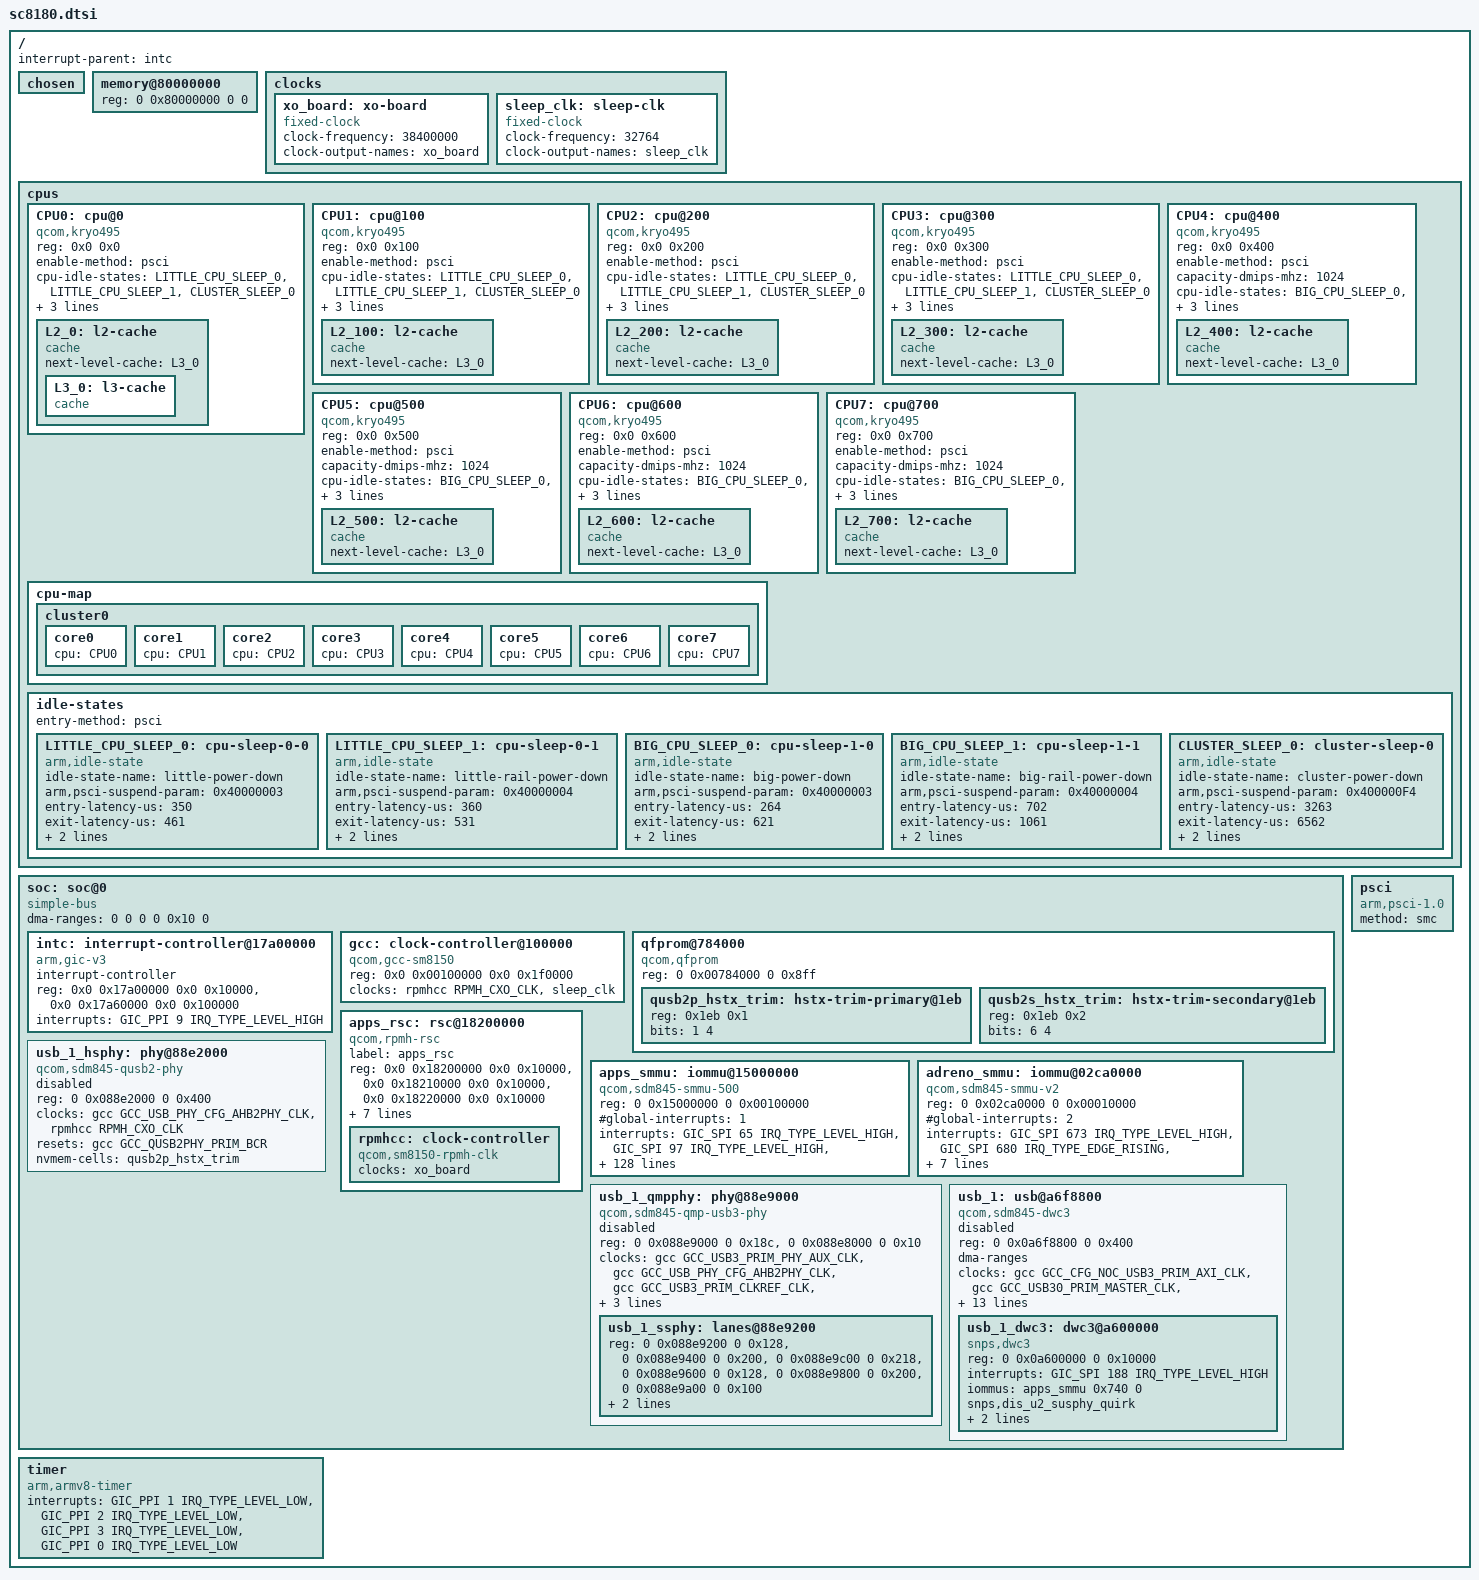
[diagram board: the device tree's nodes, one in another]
// SPDX-License-Identifier: BSD-3-Clause
#include <dt-bindings/clock/qcom,gcc-sdm845.h>
#include <dt-bindings/interrupt-controller/arm-gic.h>
#include <dt-bindings/phy/phy-qcom-qusb2.h>
#include <dt-bindings/soc/qcom,rpmh-rsc.h>
#include <dt-bindings/clock/qcom,rpmh.h>

/ {
	interrupt-parent = <&intc>;

	#address-cells = <2>;
	#size-cells = <2>;

	chosen { };

	memory@80000000 {
		device_type = "memory";
		/* We expect the bootloader to fill in the size */
		reg = <0 0x80000000 0 0>;
	};

	clocks {
		xo_board: xo-board {
			compatible = "fixed-clock";
			#clock-cells = <0>;
			clock-frequency = <38400000>;
			clock-output-names = "xo_board";
		};

		sleep_clk: sleep-clk {
			compatible = "fixed-clock";
			#clock-cells = <0>;
			clock-frequency = <32764>;
			clock-output-names = "sleep_clk";
		};
	};

	cpus {
		#address-cells = <2>;
		#size-cells = <0>;

		CPU0: cpu@0 {
			device_type = "cpu";
			compatible = "qcom,kryo495";
			reg = <0x0 0x0>;
			enable-method = "psci";
			cpu-idle-states = <&LITTLE_CPU_SLEEP_0
					   &LITTLE_CPU_SLEEP_1
					   &CLUSTER_SLEEP_0>;
			capacity-dmips-mhz = <607>;
			dynamic-power-coefficient = <100>;
			#cooling-cells = <2>;
			next-level-cache = <&L2_0>;
			L2_0: l2-cache {
				compatible = "cache";
				next-level-cache = <&L3_0>;
				L3_0: l3-cache {
				      compatible = "cache";
				};
			};
		};

		CPU1: cpu@100 {
			device_type = "cpu";
			compatible = "qcom,kryo495";
			reg = <0x0 0x100>;
			enable-method = "psci";
			cpu-idle-states = <&LITTLE_CPU_SLEEP_0
					   &LITTLE_CPU_SLEEP_1
					   &CLUSTER_SLEEP_0>;
			capacity-dmips-mhz = <607>;
			dynamic-power-coefficient = <100>;
			#cooling-cells = <2>;
			next-level-cache = <&L2_100>;
			L2_100: l2-cache {
				compatible = "cache";
				next-level-cache = <&L3_0>;
			};
		};

		CPU2: cpu@200 {
			device_type = "cpu";
			compatible = "qcom,kryo495";
			reg = <0x0 0x200>;
			enable-method = "psci";
			cpu-idle-states = <&LITTLE_CPU_SLEEP_0
					   &LITTLE_CPU_SLEEP_1
					   &CLUSTER_SLEEP_0>;
			capacity-dmips-mhz = <607>;
			dynamic-power-coefficient = <100>;
			#cooling-cells = <2>;
			next-level-cache = <&L2_200>;
			L2_200: l2-cache {
				compatible = "cache";
				next-level-cache = <&L3_0>;
			};
		};

		CPU3: cpu@300 {
			device_type = "cpu";
			compatible = "qcom,kryo495";
			reg = <0x0 0x300>;
			enable-method = "psci";
			cpu-idle-states = <&LITTLE_CPU_SLEEP_0
					   &LITTLE_CPU_SLEEP_1
					   &CLUSTER_SLEEP_0>;
			capacity-dmips-mhz = <607>;
			dynamic-power-coefficient = <100>;
			#cooling-cells = <2>;
			next-level-cache = <&L2_300>;
			L2_300: l2-cache {
				compatible = "cache";
				next-level-cache = <&L3_0>;
			};
		};

		CPU4: cpu@400 {
			device_type = "cpu";
			compatible = "qcom,kryo495";
			reg = <0x0 0x400>;
			enable-method = "psci";
			capacity-dmips-mhz = <1024>;
			cpu-idle-states = <&BIG_CPU_SLEEP_0
					   &BIG_CPU_SLEEP_1
					   &CLUSTER_SLEEP_0>;
			dynamic-power-coefficient = <396>;
			#cooling-cells = <2>;
			next-level-cache = <&L2_400>;
			L2_400: l2-cache {
				compatible = "cache";
				next-level-cache = <&L3_0>;
			};
		};

		CPU5: cpu@500 {
			device_type = "cpu";
			compatible = "qcom,kryo495";
			reg = <0x0 0x500>;
			enable-method = "psci";
			capacity-dmips-mhz = <1024>;
			cpu-idle-states = <&BIG_CPU_SLEEP_0
					   &BIG_CPU_SLEEP_1
					   &CLUSTER_SLEEP_0>;
			dynamic-power-coefficient = <396>;
			#cooling-cells = <2>;
			next-level-cache = <&L2_500>;
			L2_500: l2-cache {
				compatible = "cache";
				next-level-cache = <&L3_0>;
			};
		};

		CPU6: cpu@600 {
			device_type = "cpu";
			compatible = "qcom,kryo495";
			reg = <0x0 0x600>;
			enable-method = "psci";
			capacity-dmips-mhz = <1024>;
			cpu-idle-states = <&BIG_CPU_SLEEP_0
					   &BIG_CPU_SLEEP_1
					   &CLUSTER_SLEEP_0>;
			dynamic-power-coefficient = <396>;
			#cooling-cells = <2>;
			next-level-cache = <&L2_600>;
			L2_600: l2-cache {
				compatible = "cache";
				next-level-cache = <&L3_0>;
			};
		};

		CPU7: cpu@700 {
			device_type = "cpu";
			compatible = "qcom,kryo495";
			reg = <0x0 0x700>;
			enable-method = "psci";
			capacity-dmips-mhz = <1024>;
			cpu-idle-states = <&BIG_CPU_SLEEP_0
					   &BIG_CPU_SLEEP_1
					   &CLUSTER_SLEEP_0>;
			dynamic-power-coefficient = <396>;
			#cooling-cells = <2>;
			next-level-cache = <&L2_700>;
			L2_700: l2-cache {
				compatible = "cache";
				next-level-cache = <&L3_0>;
			};
		};

		cpu-map {
			cluster0 {
				core0 {
					cpu = <&CPU0>;
				};

				core1 {
					cpu = <&CPU1>;
				};

				core2 {
					cpu = <&CPU2>;
				};

				core3 {
					cpu = <&CPU3>;
				};

				core4 {
					cpu = <&CPU4>;
				};

				core5 {
					cpu = <&CPU5>;
				};

				core6 {
					cpu = <&CPU6>;
				};

				core7 {
					cpu = <&CPU7>;
				};
			};
		};

		idle-states {
			entry-method = "psci";

			LITTLE_CPU_SLEEP_0: cpu-sleep-0-0 {
				compatible = "arm,idle-state";
				idle-state-name = "little-power-down";
				arm,psci-suspend-param = <0x40000003>;
				entry-latency-us = <350>;
				exit-latency-us = <461>;
				min-residency-us = <1890>;
				local-timer-stop;
			};

			LITTLE_CPU_SLEEP_1: cpu-sleep-0-1 {
				compatible = "arm,idle-state";
				idle-state-name = "little-rail-power-down";
				arm,psci-suspend-param = <0x40000004>;
				entry-latency-us = <360>;
				exit-latency-us = <531>;
				min-residency-us = <3934>;
				local-timer-stop;
			};

			BIG_CPU_SLEEP_0: cpu-sleep-1-0 {
				compatible = "arm,idle-state";
				idle-state-name = "big-power-down";
				arm,psci-suspend-param = <0x40000003>;
				entry-latency-us = <264>;
				exit-latency-us = <621>;
				min-residency-us = <952>;
				local-timer-stop;
			};

			BIG_CPU_SLEEP_1: cpu-sleep-1-1 {
				compatible = "arm,idle-state";
				idle-state-name = "big-rail-power-down";
				arm,psci-suspend-param = <0x40000004>;
				entry-latency-us = <702>;
				exit-latency-us = <1061>;
				min-residency-us = <4488>;
				local-timer-stop;
			};

			CLUSTER_SLEEP_0: cluster-sleep-0 {
				compatible = "arm,idle-state";
				idle-state-name = "cluster-power-down";
				arm,psci-suspend-param = <0x400000F4>;
				entry-latency-us = <3263>;
				exit-latency-us = <6562>;
				min-residency-us = <9987>;
				local-timer-stop;
			};
		};
	};

	soc: soc@0 {
		#address-cells = <2>;
		#size-cells = <2>;
		ranges = <0 0 0 0 0x10 0>;
		dma-ranges = <0 0 0 0 0x10 0>;
		compatible = "simple-bus";

		intc: interrupt-controller@17a00000 {
			compatible = "arm,gic-v3";
			interrupt-controller;
			#interrupt-cells = <3>;
			reg = <0x0 0x17a00000 0x0 0x10000>,	/* GICD */
			      <0x0 0x17a60000 0x0 0x100000>;	/* GICR * 8 */
			interrupts = <GIC_PPI 9 IRQ_TYPE_LEVEL_HIGH>;
		};

		gcc: clock-controller@100000 {
			compatible = "qcom,gcc-sm8150";
			reg = <0x0 0x00100000 0x0 0x1f0000>;
			#clock-cells = <1>;
			#reset-cells = <1>;
			#power-domain-cells = <1>;
			clock-names = "bi_tcxo",
				      "sleep_clk";
			clocks = <&rpmhcc RPMH_CXO_CLK>,
				 <&sleep_clk>;
		};

		qfprom@784000 {
			compatible = "qcom,qfprom";
			reg = <0 0x00784000 0 0x8ff>;
			#address-cells = <1>;
			#size-cells = <1>;

			qusb2p_hstx_trim: hstx-trim-primary@1eb {
				reg = <0x1eb 0x1>;
				bits = <1 4>;
			};

			qusb2s_hstx_trim: hstx-trim-secondary@1eb {
				reg = <0x1eb 0x2>;
				bits = <6 4>;
			};
		};


		apps_rsc: rsc@18200000 {
			label = "apps_rsc";
			compatible = "qcom,rpmh-rsc";
			reg = <0x0 0x18200000 0x0 0x10000>,
			      <0x0 0x18210000 0x0 0x10000>,
			      <0x0 0x18220000 0x0 0x10000>;
			reg-names = "drv-0", "drv-1", "drv-2";
			interrupts = <GIC_SPI 3 IRQ_TYPE_LEVEL_HIGH>,
				     <GIC_SPI 4 IRQ_TYPE_LEVEL_HIGH>,
				     <GIC_SPI 5 IRQ_TYPE_LEVEL_HIGH>;
			qcom,tcs-offset = <0xd00>;
			qcom,drv-id = <2>;
			qcom,tcs-config = <ACTIVE_TCS  2>,
					  <SLEEP_TCS   1>,
					  <WAKE_TCS    1>,
					  <CONTROL_TCS 0>;

			rpmhcc: clock-controller {
				compatible = "qcom,sm8150-rpmh-clk";
				#clock-cells = <1>;
				clock-names = "xo";
				clocks = <&xo_board>;
			};
		};

		apps_smmu: iommu@15000000 {
			compatible = "qcom,sdm845-smmu-500", "arm,mmu-500";
			reg = <0 0x15000000 0 0x00100000>;
			#iommu-cells = <2>;
			#global-interrupts = <1>;
			interrupts = <GIC_SPI 65 IRQ_TYPE_LEVEL_HIGH>,
				     <GIC_SPI 97 IRQ_TYPE_LEVEL_HIGH>,
				     <GIC_SPI 98 IRQ_TYPE_LEVEL_HIGH>,
				     <GIC_SPI 99 IRQ_TYPE_LEVEL_HIGH>,
				     <GIC_SPI 100 IRQ_TYPE_LEVEL_HIGH>,
				     <GIC_SPI 101 IRQ_TYPE_LEVEL_HIGH>,
				     <GIC_SPI 102 IRQ_TYPE_LEVEL_HIGH>,
				     <GIC_SPI 103 IRQ_TYPE_LEVEL_HIGH>,
				     <GIC_SPI 104 IRQ_TYPE_LEVEL_HIGH>,
				     <GIC_SPI 105 IRQ_TYPE_LEVEL_HIGH>,
				     <GIC_SPI 106 IRQ_TYPE_LEVEL_HIGH>,
				     <GIC_SPI 107 IRQ_TYPE_LEVEL_HIGH>,
				     <GIC_SPI 108 IRQ_TYPE_LEVEL_HIGH>,
				     <GIC_SPI 109 IRQ_TYPE_LEVEL_HIGH>,
				     <GIC_SPI 110 IRQ_TYPE_LEVEL_HIGH>,
				     <GIC_SPI 111 IRQ_TYPE_LEVEL_HIGH>,
				     <GIC_SPI 112 IRQ_TYPE_LEVEL_HIGH>,
				     <GIC_SPI 113 IRQ_TYPE_LEVEL_HIGH>,
				     <GIC_SPI 114 IRQ_TYPE_LEVEL_HIGH>,
				     <GIC_SPI 115 IRQ_TYPE_LEVEL_HIGH>,
				     <GIC_SPI 116 IRQ_TYPE_LEVEL_HIGH>,
				     <GIC_SPI 117 IRQ_TYPE_LEVEL_HIGH>,
				     <GIC_SPI 118 IRQ_TYPE_LEVEL_HIGH>,
				     <GIC_SPI 181 IRQ_TYPE_LEVEL_HIGH>,
				     <GIC_SPI 182 IRQ_TYPE_LEVEL_HIGH>,
				     <GIC_SPI 183 IRQ_TYPE_LEVEL_HIGH>,
				     <GIC_SPI 184 IRQ_TYPE_LEVEL_HIGH>,
				     <GIC_SPI 185 IRQ_TYPE_LEVEL_HIGH>,
				     <GIC_SPI 186 IRQ_TYPE_LEVEL_HIGH>,
				     <GIC_SPI 187 IRQ_TYPE_LEVEL_HIGH>,
				     <GIC_SPI 188 IRQ_TYPE_LEVEL_HIGH>,
				     <GIC_SPI 189 IRQ_TYPE_LEVEL_HIGH>,
				     <GIC_SPI 190 IRQ_TYPE_LEVEL_HIGH>,
				     <GIC_SPI 191 IRQ_TYPE_LEVEL_HIGH>,
				     <GIC_SPI 192 IRQ_TYPE_LEVEL_HIGH>,
				     <GIC_SPI 315 IRQ_TYPE_LEVEL_HIGH>,
				     <GIC_SPI 316 IRQ_TYPE_LEVEL_HIGH>,
				     <GIC_SPI 317 IRQ_TYPE_LEVEL_HIGH>,
				     <GIC_SPI 318 IRQ_TYPE_LEVEL_HIGH>,
				     <GIC_SPI 319 IRQ_TYPE_LEVEL_HIGH>,
				     <GIC_SPI 320 IRQ_TYPE_LEVEL_HIGH>,
				     <GIC_SPI 321 IRQ_TYPE_LEVEL_HIGH>,
				     <GIC_SPI 322 IRQ_TYPE_LEVEL_HIGH>,
				     <GIC_SPI 323 IRQ_TYPE_LEVEL_HIGH>,
				     <GIC_SPI 324 IRQ_TYPE_LEVEL_HIGH>,
				     <GIC_SPI 325 IRQ_TYPE_LEVEL_HIGH>,
				     <GIC_SPI 326 IRQ_TYPE_LEVEL_HIGH>,
				     <GIC_SPI 327 IRQ_TYPE_LEVEL_HIGH>,
				     <GIC_SPI 328 IRQ_TYPE_LEVEL_HIGH>,
				     <GIC_SPI 329 IRQ_TYPE_LEVEL_HIGH>,
				     <GIC_SPI 330 IRQ_TYPE_LEVEL_HIGH>,
				     <GIC_SPI 331 IRQ_TYPE_LEVEL_HIGH>,
				     <GIC_SPI 332 IRQ_TYPE_LEVEL_HIGH>,
				     <GIC_SPI 333 IRQ_TYPE_LEVEL_HIGH>,
				     <GIC_SPI 334 IRQ_TYPE_LEVEL_HIGH>,
				     <GIC_SPI 335 IRQ_TYPE_LEVEL_HIGH>,
				     <GIC_SPI 336 IRQ_TYPE_LEVEL_HIGH>,
				     <GIC_SPI 337 IRQ_TYPE_LEVEL_HIGH>,
				     <GIC_SPI 338 IRQ_TYPE_LEVEL_HIGH>,
				     <GIC_SPI 339 IRQ_TYPE_LEVEL_HIGH>,
				     <GIC_SPI 340 IRQ_TYPE_LEVEL_HIGH>,
				     <GIC_SPI 341 IRQ_TYPE_LEVEL_HIGH>,
				     <GIC_SPI 342 IRQ_TYPE_LEVEL_HIGH>,
				     <GIC_SPI 343 IRQ_TYPE_LEVEL_HIGH>,
				     <GIC_SPI 344 IRQ_TYPE_LEVEL_HIGH>,
				     <GIC_SPI 345 IRQ_TYPE_LEVEL_HIGH>,
				     <GIC_SPI 395 IRQ_TYPE_LEVEL_HIGH>,
				     <GIC_SPI 396 IRQ_TYPE_LEVEL_HIGH>,
				     <GIC_SPI 397 IRQ_TYPE_LEVEL_HIGH>,
				     <GIC_SPI 398 IRQ_TYPE_LEVEL_HIGH>,
				     <GIC_SPI 399 IRQ_TYPE_LEVEL_HIGH>,
				     <GIC_SPI 400 IRQ_TYPE_LEVEL_HIGH>,
				     <GIC_SPI 401 IRQ_TYPE_LEVEL_HIGH>,
				     <GIC_SPI 402 IRQ_TYPE_LEVEL_HIGH>,
				     <GIC_SPI 403 IRQ_TYPE_LEVEL_HIGH>,
				     <GIC_SPI 404 IRQ_TYPE_LEVEL_HIGH>,
				     <GIC_SPI 405 IRQ_TYPE_LEVEL_HIGH>,
				     <GIC_SPI 406 IRQ_TYPE_LEVEL_HIGH>,
				     <GIC_SPI 407 IRQ_TYPE_LEVEL_HIGH>,
				     <GIC_SPI 408 IRQ_TYPE_LEVEL_HIGH>,
				     <GIC_SPI 409 IRQ_TYPE_LEVEL_HIGH>,
				     <GIC_SPI 410 IRQ_TYPE_LEVEL_HIGH>,
				     <GIC_SPI 411 IRQ_TYPE_LEVEL_HIGH>,
				     <GIC_SPI 412 IRQ_TYPE_LEVEL_HIGH>,
				     <GIC_SPI 413 IRQ_TYPE_LEVEL_HIGH>,
				     <GIC_SPI 640 IRQ_TYPE_LEVEL_HIGH>,
				     <GIC_SPI 641 IRQ_TYPE_LEVEL_HIGH>,
				     <GIC_SPI 642 IRQ_TYPE_LEVEL_HIGH>,
				     <GIC_SPI 643 IRQ_TYPE_LEVEL_HIGH>,
				     <GIC_SPI 706 IRQ_TYPE_LEVEL_HIGH>,
				     <GIC_SPI 707 IRQ_TYPE_LEVEL_HIGH>,
				     <GIC_SPI 708 IRQ_TYPE_LEVEL_HIGH>,
				     <GIC_SPI 709 IRQ_TYPE_LEVEL_HIGH>,
				     <GIC_SPI 710 IRQ_TYPE_LEVEL_HIGH>,
				     <GIC_SPI 711 IRQ_TYPE_LEVEL_HIGH>,
				     <GIC_SPI 712 IRQ_TYPE_LEVEL_HIGH>,
				     <GIC_SPI 713 IRQ_TYPE_LEVEL_HIGH>,
				     <GIC_SPI 714 IRQ_TYPE_LEVEL_HIGH>,
				     <GIC_SPI 715 IRQ_TYPE_LEVEL_HIGH>,
				     <GIC_SPI 768 IRQ_TYPE_LEVEL_HIGH>,
				     <GIC_SPI 769 IRQ_TYPE_LEVEL_HIGH>,
				     <GIC_SPI 770 IRQ_TYPE_LEVEL_HIGH>,
				     <GIC_SPI 771 IRQ_TYPE_LEVEL_HIGH>,
				     <GIC_SPI 772 IRQ_TYPE_LEVEL_HIGH>,
				     <GIC_SPI 773 IRQ_TYPE_LEVEL_HIGH>,
				     <GIC_SPI 774 IRQ_TYPE_LEVEL_HIGH>,
				     <GIC_SPI 775 IRQ_TYPE_LEVEL_HIGH>,
				     <GIC_SPI 776 IRQ_TYPE_LEVEL_HIGH>,
				     <GIC_SPI 777 IRQ_TYPE_LEVEL_HIGH>,
				     <GIC_SPI 778 IRQ_TYPE_LEVEL_HIGH>,
				     <GIC_SPI 779 IRQ_TYPE_LEVEL_HIGH>,
				     <GIC_SPI 780 IRQ_TYPE_LEVEL_HIGH>,
				     <GIC_SPI 781 IRQ_TYPE_LEVEL_HIGH>,
				     <GIC_SPI 782 IRQ_TYPE_LEVEL_HIGH>,
				     <GIC_SPI 783 IRQ_TYPE_LEVEL_HIGH>,
				     <GIC_SPI 784 IRQ_TYPE_LEVEL_HIGH>,
				     <GIC_SPI 785 IRQ_TYPE_LEVEL_HIGH>,
				     <GIC_SPI 786 IRQ_TYPE_LEVEL_HIGH>,
				     <GIC_SPI 787 IRQ_TYPE_LEVEL_HIGH>,
				     <GIC_SPI 788 IRQ_TYPE_LEVEL_HIGH>,
				     <GIC_SPI 789 IRQ_TYPE_LEVEL_HIGH>,
				     <GIC_SPI 790 IRQ_TYPE_LEVEL_HIGH>,
				     <GIC_SPI 791 IRQ_TYPE_LEVEL_HIGH>,
				     <GIC_SPI 792 IRQ_TYPE_LEVEL_HIGH>,
				     <GIC_SPI 793 IRQ_TYPE_LEVEL_HIGH>,
				     <GIC_SPI 794 IRQ_TYPE_LEVEL_HIGH>,
				     <GIC_SPI 795 IRQ_TYPE_LEVEL_HIGH>,
				     <GIC_SPI 796 IRQ_TYPE_LEVEL_HIGH>,
				     <GIC_SPI 797 IRQ_TYPE_LEVEL_HIGH>;
			qcom,smmu-500-fw-impl-errata;
		};

		adreno_smmu: iommu@02ca0000 {
			compatible = "qcom,sdm845-smmu-v2", "qcom,smmu-v2";
			reg = <0 0x02ca0000 0 0x00010000>;
			#iommu-cells = <1>;
			#global-interrupts = <2>;
			interrupts = <GIC_SPI 673 IRQ_TYPE_LEVEL_HIGH>,
				     <GIC_SPI 680 IRQ_TYPE_EDGE_RISING>,
				     <GIC_SPI 681 IRQ_TYPE_EDGE_RISING>,
				     <GIC_SPI 682 IRQ_TYPE_EDGE_RISING>,
				     <GIC_SPI 683 IRQ_TYPE_EDGE_RISING>,
				     <GIC_SPI 684 IRQ_TYPE_EDGE_RISING>,
				     <GIC_SPI 685 IRQ_TYPE_EDGE_RISING>,
				     <GIC_SPI 686 IRQ_TYPE_EDGE_RISING>,
				     <GIC_SPI 687 IRQ_TYPE_EDGE_RISING>;
		};

		usb_1_hsphy: phy@88e2000 {
			compatible = "qcom,sdm845-qusb2-phy";
			reg = <0 0x088e2000 0 0x400>;
			status = "disabled";
			#phy-cells = <0>;

			clocks = <&gcc GCC_USB_PHY_CFG_AHB2PHY_CLK>,
				 <&rpmhcc RPMH_CXO_CLK>;
			clock-names = "cfg_ahb", "ref";

			resets = <&gcc GCC_QUSB2PHY_PRIM_BCR>;

			nvmem-cells = <&qusb2p_hstx_trim>;
		};

		usb_1_qmpphy: phy@88e9000 {
			compatible = "qcom,sdm845-qmp-usb3-phy";
			reg = <0 0x088e9000 0 0x18c>,
			      <0 0x088e8000 0 0x10>;
			reg-names = "reg-base", "dp_com";
			status = "disabled";
			#clock-cells = <1>;
			#address-cells = <2>;
			#size-cells = <2>;
			ranges;

			clocks = <&gcc GCC_USB3_PRIM_PHY_AUX_CLK>,
				 <&gcc GCC_USB_PHY_CFG_AHB2PHY_CLK>,
				 <&gcc GCC_USB3_PRIM_CLKREF_CLK>,
				 <&gcc GCC_USB3_PRIM_PHY_COM_AUX_CLK>;
			clock-names = "aux", "cfg_ahb", "ref", "com_aux";

			resets = <&gcc GCC_USB3_DP_PHY_PRIM_BCR>,
				 <&gcc GCC_USB3_PHY_PRIM_BCR>;
			reset-names = "phy", "common";

			usb_1_ssphy: lanes@88e9200 {
				reg = <0 0x088e9200 0 0x128>,
				      <0 0x088e9400 0 0x200>,
				      <0 0x088e9c00 0 0x218>,
				      <0 0x088e9600 0 0x128>,
				      <0 0x088e9800 0 0x200>,
				      <0 0x088e9a00 0 0x100>;
				#phy-cells = <0>;
				clocks = <&gcc GCC_USB3_PRIM_PHY_PIPE_CLK>;
				clock-names = "pipe0";
				clock-output-names = "usb3_phy_pipe_clk_src";
			};
		};

		usb_1: usb@a6f8800 {
			compatible = "qcom,sdm845-dwc3", "qcom,dwc3";
			reg = <0 0x0a6f8800 0 0x400>;
			status = "disabled";
			#address-cells = <2>;
			#size-cells = <2>;
			ranges;
			dma-ranges;

			clocks = <&gcc GCC_CFG_NOC_USB3_PRIM_AXI_CLK>,
				 <&gcc GCC_USB30_PRIM_MASTER_CLK>,
				 <&gcc GCC_AGGRE_USB3_PRIM_AXI_CLK>,
				 <&gcc GCC_USB30_PRIM_MOCK_UTMI_CLK>,
				 <&gcc GCC_USB30_PRIM_SLEEP_CLK>;
			clock-names = "cfg_noc", "core", "iface", "mock_utmi",
				      "sleep";

			assigned-clocks = <&gcc GCC_USB30_PRIM_MOCK_UTMI_CLK>,
					  <&gcc GCC_USB30_PRIM_MASTER_CLK>;
			assigned-clock-rates = <19200000>, <150000000>;

			interrupts = <GIC_SPI 186 IRQ_TYPE_LEVEL_HIGH>,
				     <GIC_SPI 189 IRQ_TYPE_LEVEL_HIGH>,
				     <GIC_SPI 190 IRQ_TYPE_LEVEL_HIGH>,
				     <GIC_SPI 191 IRQ_TYPE_LEVEL_HIGH>;
			interrupt-names = "hs_phy_irq", "ss_phy_irq",
					  "dm_hs_phy_irq", "dp_hs_phy_irq";

			power-domains = <&gcc USB30_PRIM_GDSC>;

			resets = <&gcc GCC_USB30_PRIM_BCR>;

			usb_1_dwc3: dwc3@a600000 {
				compatible = "snps,dwc3";
				reg = <0 0x0a600000 0 0x10000>;
				interrupts = <GIC_SPI 188 IRQ_TYPE_LEVEL_HIGH>;
				iommus = <&apps_smmu 0x740 0>;
				snps,dis_u2_susphy_quirk;
				snps,dis_enblslpm_quirk;
				phys = <&usb_1_hsphy>, <&usb_1_ssphy>;
				phy-names = "usb2-phy", "usb3-phy";
			};
		};
	};

	psci {
		compatible = "arm,psci-1.0";
		method = "smc";
	};

	timer {
		compatible = "arm,armv8-timer";
		interrupts = <GIC_PPI 1 IRQ_TYPE_LEVEL_LOW>,
			     <GIC_PPI 2 IRQ_TYPE_LEVEL_LOW>,
			     <GIC_PPI 3 IRQ_TYPE_LEVEL_LOW>,
			     <GIC_PPI 0 IRQ_TYPE_LEVEL_LOW>;
	};
};

